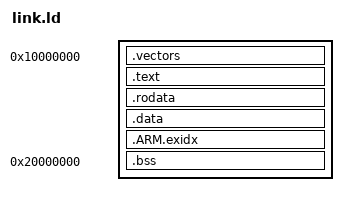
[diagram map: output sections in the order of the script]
SECTIONS {
    . = 0x10000000;

    .vectors : {
        LONG(_stack_end | 1)
        LONG(_start | 1)
        LONG(_int_handler | 1)
        LONG(_int_handler | 1)
        LONG(_int_handler | 1)
        LONG(_int_handler | 1)
        LONG(_int_handler | 1)
        LONG(_int_handler | 1)
        LONG(_int_handler | 1)
        LONG(_int_handler | 1)
        LONG(_int_handler | 1)
        LONG(_int_handler | 1)
        LONG(_int_handler | 1)
        LONG(_int_handler | 1)
        LONG(_int_handler | 1)
        LONG(_int_handler | 1)
        LONG(_int_handler | 1)
        LONG(_int_handler | 1)
        LONG(_int_handler | 1)
        LONG(_int_handler | 1)
        LONG(_int_handler | 1)
        LONG(_int_handler | 1)
        LONG(_int_handler | 1)
        LONG(_int_handler | 1)
        LONG(_int_handler | 1)
        LONG(_int_handler | 1)
        LONG(_int_handler | 1)
        LONG(_int_handler | 1)
        LONG(_int_handler | 1)
        LONG(_int_handler | 1)
        LONG(_int_handler | 1)
        LONG(_int_handler | 1)
        LONG(_int_handler | 1)
        LONG(_int_handler | 1)
        LONG(_int_handler | 1)
        LONG(_int_handler | 1)
        LONG(_int_handler | 1)
        LONG(_int_handler | 1)
        LONG(_int_handler | 1)
        LONG(_int_handler | 1)
        LONG(_int_handler | 1)
        LONG(_int_handler | 1)
        LONG(_int_handler | 1)
        LONG(_int_handler | 1)
        LONG(_int_handler | 1)
        LONG(_int_handler | 1)
        LONG(_int_handler | 1)
        LONG(_int_handler | 1)
        LONG(_int_handler | 1)
        LONG(_int_handler | 1)
        LONG(_int_handler | 1)
        LONG(_int_handler | 1)
        LONG(_int_handler | 1)
        LONG(_int_handler | 1)
        LONG(_int_handler | 1)
        LONG(_int_handler | 1)
        LONG(_int_handler | 1)
        LONG(_int_handler | 1)
        LONG(_int_handler | 1)
        LONG(_int_handler | 1)
        LONG(_int_handler | 1)
        LONG(_int_handler | 1)
        LONG(_int_handler | 1)
        LONG(_int_handler | 1)
        LONG(_int_handler | 1)
        LONG(_int_handler | 1)
        LONG(_int_handler | 1)
        LONG(_int_handler | 1)
        LONG(_int_handler | 1)
        LONG(_int_handler | 1)
        LONG(_int_handler | 1)
        LONG(_int_handler | 1)
        LONG(_int_handler | 1)
        LONG(_int_handler | 1)
        LONG(_int_handler | 1)
        LONG(_int_handler | 1)
        LONG(_int_handler | 1)
        LONG(_int_handler | 1)
        LONG(_int_handler | 1)
        LONG(_int_handler | 1)
        LONG(_int_handler | 1)
        LONG(_int_handler | 1)
        LONG(_int_handler | 1)
        LONG(_int_handler | 1)
        LONG(_int_handler | 1)
        LONG(_int_handler | 1)
        LONG(_int_handler | 1)
        LONG(_int_handler | 1)
        LONG(_int_handler | 1)
        LONG(_int_handler | 1)
        LONG(_int_handler | 1)
        LONG(_int_handler | 1)
        LONG(_int_handler | 1)
        LONG(_int_handler | 1)
        LONG(_int_handler | 1)
        LONG(_int_handler | 1)
        LONG(_int_handler | 1)
        LONG(_int_handler | 1)
        LONG(_int_handler | 1)
        LONG(_int_handler | 1)
        LONG(_int_handler | 1)
        LONG(_int_handler | 1)
        LONG(_int_handler | 1)
        LONG(_int_handler | 1)
        LONG(_int_handler | 1)
        LONG(_int_handler | 1)
        LONG(_int_handler | 1)
        LONG(_int_handler | 1)
        LONG(_int_handler | 1)
        LONG(_int_handler | 1)
        LONG(_int_handler | 1)
        LONG(_int_handler | 1)
        LONG(_int_handler | 1)
        LONG(_int_handler | 1)
        LONG(_int_handler | 1)
        LONG(_int_handler | 1)
        LONG(_int_handler | 1)
        LONG(_int_handler | 1)
        LONG(_int_handler | 1)
        LONG(_int_handler | 1)
        LONG(_int_handler | 1)
        LONG(_int_handler | 1)
        LONG(_int_handler | 1)
        LONG(_int_handler | 1)
        LONG(_int_handler | 1)
        LONG(_int_handler | 1)
        LONG(_int_handler | 1)
        LONG(_int_handler | 1)
        LONG(_int_handler | 1)
        LONG(_int_handler | 1)
        LONG(_int_handler | 1)
        LONG(_int_handler | 1)
        LONG(_int_handler | 1)
        LONG(_int_handler | 1)
        LONG(_int_handler | 1)
        LONG(_int_handler | 1)
        LONG(_int_handler | 1)
        LONG(_int_handler | 1)
        LONG(_int_handler | 1)
        LONG(_int_handler | 1)
        LONG(_int_handler | 1)
        LONG(_int_handler | 1)
        LONG(_int_handler | 1)
        LONG(_int_handler | 1)
        LONG(_int_handler | 1)
        LONG(_int_handler | 1)
        LONG(_int_handler | 1)
        LONG(_int_handler | 1)
        LONG(_int_handler | 1)
        LONG(_int_handler | 1)
        LONG(_int_handler | 1)
        LONG(_int_handler | 1)
        LONG(_int_handler | 1)
        LONG(_int_handler | 1)
        LONG(_int_handler | 1)
        LONG(_int_handler | 1)
        LONG(_int_handler | 1)
        LONG(_int_handler | 1)
        LONG(_int_handler | 1)
        LONG(_int_handler | 1)
        LONG(_int_handler | 1)
        LONG(_int_handler | 1)
        LONG(_int_handler | 1)
        LONG(_int_handler | 1)
        LONG(_int_handler | 1)
        LONG(_int_handler | 1)
        LONG(_int_handler | 1)
        LONG(_int_handler | 1)
        LONG(_int_handler | 1)
        LONG(_int_handler | 1)
        LONG(_int_handler | 1)
        LONG(_int_handler | 1)
        LONG(_int_handler | 1)
        LONG(_int_handler | 1)
        LONG(_int_handler | 1)
        LONG(_int_handler | 1)
        LONG(_int_handler | 1)
        LONG(_int_handler | 1)
        LONG(_int_handler | 1)
        LONG(_int_handler | 1)
        LONG(_int_handler | 1)
        LONG(_int_handler | 1)
        LONG(_int_handler | 1)
        LONG(_int_handler | 1)
        LONG(_int_handler | 1)
        LONG(_int_handler | 1)
        LONG(_int_handler | 1)
        LONG(_int_handler | 1)
        LONG(_int_handler | 1)
        LONG(_int_handler | 1)
        LONG(_int_handler | 1)
        LONG(_int_handler | 1)
        LONG(_int_handler | 1)
        LONG(_int_handler | 1)
        LONG(_int_handler | 1)
        LONG(_int_handler | 1)
        LONG(_int_handler | 1)
        LONG(_int_handler | 1)
        LONG(_int_handler | 1)
        LONG(_int_handler | 1)
        LONG(_int_handler | 1)
        LONG(_int_handler | 1)
        LONG(_int_handler | 1)
        LONG(_int_handler | 1)
        LONG(_int_handler | 1)
        LONG(_int_handler | 1)
        LONG(_int_handler | 1)
        LONG(_int_handler | 1)
        LONG(_int_handler | 1)
        LONG(_int_handler | 1)
        LONG(_int_handler | 1)
        LONG(_int_handler | 1)
        LONG(_int_handler | 1)
        LONG(_int_handler | 1)
        LONG(_int_handler | 1)
        LONG(_int_handler | 1)
        LONG(_int_handler | 1)
        LONG(_int_handler | 1)
        LONG(_int_handler | 1)
        LONG(_int_handler | 1)
        LONG(_int_handler | 1)
        LONG(_int_handler | 1)
        LONG(_int_handler | 1)
        LONG(_int_handler | 1)
        LONG(_int_handler | 1)
        LONG(_int_handler | 1)
        LONG(_int_handler | 1)
        LONG(_int_handler | 1)
        LONG(_int_handler | 1)
        LONG(_int_handler | 1)
        LONG(_int_handler | 1)
        LONG(_int_handler | 1)
        LONG(_int_handler | 1)
        LONG(_int_handler | 1)
        LONG(_int_handler | 1)
        LONG(_int_handler | 1)
        LONG(_int_handler | 1)
        LONG(_int_handler | 1)
        LONG(_int_handler | 1)
        LONG(_int_handler | 1)
        LONG(_int_handler | 1)
        LONG(_int_handler | 1)
        LONG(_int_handler | 1)
        LONG(_int_handler | 1)
        LONG(_int_handler | 1)
        LONG(_int_handler | 1)
        LONG(_int_handler | 1)
        LONG(_int_handler | 1)
        LONG(_int_handler | 1)
        LONG(_int_handler | 1)
        LONG(_int_handler | 1)
        LONG(_int_handler | 1)
        LONG(_int_handler | 1)
        LONG(_int_handler | 1)
        LONG(_int_handler | 1)
        LONG(_int_handler | 1)

        *(.vectors*)
    }

    .text : {
        LONG(0xffffded3),
        LONG(0x10210142),
        LONG(0x000001ff),
        LONG(0x00000000),
        LONG(0xab123579),

        *(.text*)
    }
    .rodata : { *(.rodata*) }
    .data : { *(.data*) }
    .ARM.exidx : { *(.ARM.exidx*) }

    . = 0x20000000;
    .bss : {
        *(.bss*)
        
        . = ALIGN(0x1000);
        PROVIDE (_stack_start = .);
        . += 0x1000;
        PROVIDE (_stack_end = .);
    }

    PROVIDE (_kernel_end = .);
}
